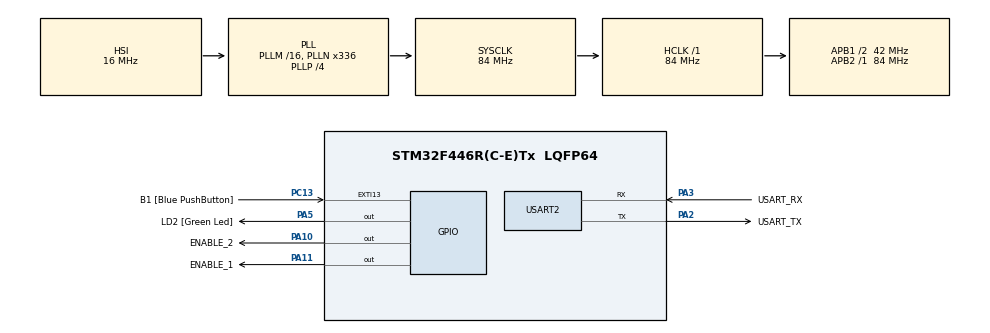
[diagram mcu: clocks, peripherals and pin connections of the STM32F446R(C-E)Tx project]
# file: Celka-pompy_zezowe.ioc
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Mcu.Family=STM32F4
PH0-OSC_IN.Signal=RCC_OSC_IN
VP_SYS_VS_tim6.Mode=TIM6
RCC.CortexFreq_Value=84000000
FREERTOS.BinarySemaphores01=decoder_sem,Dynamic,NULL
NVIC.TIM6_DAC_IRQn=true\:0\:0\:false\:false\:true\:false\:false\:true
PA14.GPIO_Label=TCK
PC13.GPIO_Label=B1 [Blue PushButton]
RCC.SYSCLKSource=RCC_SYSCLKSOURCE_PLLCLK
ProjectManager.StackSize=0x400
RCC.HCLKFreq_Value=84000000
RCC.APB2TimFreq_Value=84000000
RCC.AHBFreq_Value=84000000
PH0-OSC_IN.Mode=HSE-External-Oscillator
FREERTOS.configUSE_PREEMPTION=1
RCC.HSE_VALUE=8000000
PC14-OSC32_IN.Mode=LSE-External-Oscillator
PA14.Mode=Serial_Wire
PA10.GPIO_Label=ENABLE_2
VP_FREERTOS_VS_CMSIS_V1.Mode=CMSIS_V1
RCC.FLatency-AdvancedSettings=FLASH_LATENCY_2
PH1-OSC_OUT.Mode=HSE-External-Oscillator
Mcu.Package=LQFP64
NVIC.TimeBase=TIM6_DAC_IRQn
USART2.VirtualMode=VM_ASYNC
PA2.GPIO_Label=USART_TX
NVIC.TimeBaseIP=TIM6
PA10.Signal=GPIO_Output
RCC.APB1TimFreq_Value=84000000
PA3.Signal=USART2_RX
PB3.GPIO_Label=SWO
PC15-OSC32_OUT.Mode=LSE-External-Oscillator
FREERTOS.Tasks01=defaultTask,0,128,StartDefaultTask,Default,NULL,Dynamic,NULL,NULL;TaskComm,0,256,StartTaskCommunication,As external,NULL,Dynamic,NULL,NULL;task_bilge_pump,0,256,Start_Task_PumpControl,As external,NULL,Dynamic,NULL,NULL
PC13.Signal=GPXTI13
PA11.GPIO_Label=ENABLE_1
RCC.APB1CLKDivider=RCC_HCLK_DIV2
PC14-OSC32_IN.Signal=RCC_OSC32_IN
NVIC.USART2_IRQn=true\:5\:0\:false\:false\:true\:true\:true\:true
PA13.Signal=SYS_JTMS-SWDIO
PA3.Mode=Asynchronous
ProjectManager.TargetToolchain=STM32CubeIDE
RCC.USBFreq_Value=168000000
PC15-OSC32_OUT.Signal=RCC_OSC32_OUT
PA5.Signal=GPIO_Output
board=NUCLEO-F446RE
RCC.VCOOutputFreq_Value=336000000
RCC.APB2Freq_Value=84000000
PH1-OSC_OUT.Signal=RCC_OSC_OUT
PA13.Mode=Serial_Wire
Mcu.Name=STM32F446R(C-E)Tx
PA13.GPIO_Label=TMS
PA2.Signal=USART2_TX
RCC.48MHZClocksFreq_Value=84000000
PB3.Signal=SYS_JTDO-SWO
RCC.SYSCLKFreq_VALUE=84000000
FREERTOS.configUSE_COUNTING_SEMAPHORES=1
PA5.GPIO_Label=LD2 [Green Led]
PC13.GPIO_ModeDefaultEXTI=GPIO_MODE_IT_FALLING
PA11.Signal=GPIO_Output
PA14.Signal=SYS_JTCK-SWCLK
ProjectManager.HeapSize=0x200
RCC.HSI_VALUE=16000000
RCC.PLLP=RCC_PLLP_DIV4
NVIC.PriorityGroup=NVIC_PRIORITYGROUP_4
RCC.PLLN=336
PA2.Mode=Asynchronous
RCC.APB1Freq_Value=42000000
PA3.GPIO_Label=USART_RX

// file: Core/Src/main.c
/* USER CODE BEGIN Header */
/**
  ******************************************************************************
  * @file           : main.c
  * @brief          : Main program body
  ******************************************************************************
  * @attention
  *
  * <h2><center>&copy; Copyright (c) 2021 STMicroelectronics.
  * All rights reserved.</center></h2>
  *
  * This software component is licensed by ST under Ultimate Liberty license
  * SLA0044, the "License"; You may not use this file except in compliance with
  * the License. You may obtain a copy of the License at:
  *                             www.st.com/SLA0044
  *
  ******************************************************************************
  */
/* USER CODE END Header */

#include "main.h"
#include "cmsis_os.h"
#include "usart.h"
#include "gpio.h"

void SystemClock_Config(void);
void MX_FREERTOS_Init(void);

int main(void)
{

  /* MCU Configuration--------------------------------------------------------*/

  /* Reset of all peripherals, Initializes the Flash interface and the Systick. */
  HAL_Init();

  /* Configure the system clock */
  SystemClock_Config();

  /* Initialize all configured peripherals */
  MX_GPIO_Init();
  MX_USART2_UART_Init();

  /* Call init function for freertos objects (in freertos.c) */
  MX_FREERTOS_Init();
  /* Start scheduler */
  osKernelStart();

  /* We should never get here as control is now taken by the scheduler */
  /* Infinite loop */
  while (1)
  {

  }
}

void SystemClock_Config(void)
{
  RCC_OscInitTypeDef RCC_OscInitStruct = {0};
  RCC_ClkInitTypeDef RCC_ClkInitStruct = {0};

  /** Configure the main internal regulator output voltage
  */
  __HAL_RCC_PWR_CLK_ENABLE();
  __HAL_PWR_VOLTAGESCALING_CONFIG(PWR_REGULATOR_VOLTAGE_SCALE3);
  /** Initializes the CPU, AHB and APB busses clocks
  */
  RCC_OscInitStruct.OscillatorType = RCC_OSCILLATORTYPE_HSI;
  RCC_OscInitStruct.HSIState = RCC_HSI_ON;
  RCC_OscInitStruct.HSICalibrationValue = RCC_HSICALIBRATION_DEFAULT;
  RCC_OscInitStruct.PLL.PLLState = RCC_PLL_ON;
  RCC_OscInitStruct.PLL.PLLSource = RCC_PLLSOURCE_HSI;
  RCC_OscInitStruct.PLL.PLLM = 16;
  RCC_OscInitStruct.PLL.PLLN = 336;
  RCC_OscInitStruct.PLL.PLLP = RCC_PLLP_DIV4;
  RCC_OscInitStruct.PLL.PLLQ = 2;
  RCC_OscInitStruct.PLL.PLLR = 2;
  if (HAL_RCC_OscConfig(&RCC_OscInitStruct) != HAL_OK)
  {
    Error_Handler();
  }
  /** Initializes the CPU, AHB and APB busses clocks
  */
  RCC_ClkInitStruct.ClockType = RCC_CLOCKTYPE_HCLK|RCC_CLOCKTYPE_SYSCLK
                              |RCC_CLOCKTYPE_PCLK1|RCC_CLOCKTYPE_PCLK2;
  RCC_ClkInitStruct.SYSCLKSource = RCC_SYSCLKSOURCE_PLLCLK;
  RCC_ClkInitStruct.AHBCLKDivider = RCC_SYSCLK_DIV1;
  RCC_ClkInitStruct.APB1CLKDivider = RCC_HCLK_DIV2;
  RCC_ClkInitStruct.APB2CLKDivider = RCC_HCLK_DIV1;

  if (HAL_RCC_ClockConfig(&RCC_ClkInitStruct, FLASH_LATENCY_2) != HAL_OK)
  {
    Error_Handler();
  }
}

 /**
  * @brief  Period elapsed callback in non blocking mode
  * @note   This function is called  when TIM6 interrupt took place, inside
  * HAL_TIM_IRQHandler(). It makes a direct call to HAL_IncTick() to increment
  * a global variable "uwTick" used as application time base.
  * @param  htim : TIM handle
  * @retval None
  */
void HAL_TIM_PeriodElapsedCallback(TIM_HandleTypeDef *htim)
{
  if (htim->Instance == TIM6) {
    HAL_IncTick();
  }
}

void Error_Handler(void)
{
}

/************************ (C) COPYRIGHT STMicroelectronics *****END OF FILE****/

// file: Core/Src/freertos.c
/* USER CODE BEGIN Header */
/**
  ******************************************************************************
  * File Name          : freertos.c
  * Description        : Code for freertos applications
  ******************************************************************************
  * @attention
  *
  * <h2><center>&copy; Copyright (c) 2021 STMicroelectronics.
  * All rights reserved.</center></h2>
  *
  * This software component is licensed by ST under Ultimate Liberty license
  * SLA0044, the "License"; You may not use this file except in compliance with
  * the License. You may obtain a copy of the License at:
  *                             www.st.com/SLA0044
  *
  ******************************************************************************
  */
/* USER CODE END Header */

#include "FreeRTOS.h"
#include "task.h"
#include "main.h"
#include "cmsis_os.h"

/* USER CODE BEGIN Includes */
#include "taskCommunication.h"
#include "task_bilge_pump.h"
/* USER CODE END Includes */

osThreadId defaultTaskHandle;
osThreadId TaskCommHandle;
osThreadId task_bilge_pumpHandle;
osSemaphoreId decoder_semHandle;

void StartDefaultTask(void const * argument);
extern void StartTaskCommunication(void const * argument);
extern void Start_Task_PumpControl(void const * argument);

void MX_FREERTOS_Init(void); /* (MISRA C 2004 rule 8.1) */

/* GetIdleTaskMemory prototype (linked to static allocation support) */
void vApplicationGetIdleTaskMemory( StaticTask_t **ppxIdleTaskTCBBuffer, StackType_t **ppxIdleTaskStackBuffer, uint32_t *pulIdleTaskStackSize );

/* USER CODE BEGIN GET_IDLE_TASK_MEMORY */
static StaticTask_t xIdleTaskTCBBuffer;
static StackType_t xIdleStack[configMINIMAL_STACK_SIZE];

void vApplicationGetIdleTaskMemory( StaticTask_t **ppxIdleTaskTCBBuffer, StackType_t **ppxIdleTaskStackBuffer, uint32_t *pulIdleTaskStackSize )
{
  *ppxIdleTaskTCBBuffer = &xIdleTaskTCBBuffer;
  *ppxIdleTaskStackBuffer = &xIdleStack[0];
  *pulIdleTaskStackSize = configMINIMAL_STACK_SIZE;
  /* place for user code */
}
/* USER CODE END GET_IDLE_TASK_MEMORY */

void MX_FREERTOS_Init(void) {

  /* Create the semaphores(s) */
  /* definition and creation of decoder_sem */
  osSemaphoreDef(decoder_sem);
  decoder_semHandle = osSemaphoreCreate(osSemaphore(decoder_sem), 1);

  /* Create the thread(s) */
  /* definition and creation of defaultTask */
  osThreadDef(defaultTask, StartDefaultTask, osPriorityNormal, 0, 128);
  defaultTaskHandle = osThreadCreate(osThread(defaultTask), NULL);

  /* definition and creation of TaskComm */
  osThreadDef(TaskComm, StartTaskCommunication, osPriorityNormal, 0, 256);
  TaskCommHandle = osThreadCreate(osThread(TaskComm), NULL);

  /* definition and creation of task_bilge_pump */
  osThreadDef(task_bilge_pump, Start_Task_PumpControl, osPriorityNormal, 0, 256);
  task_bilge_pumpHandle = osThreadCreate(osThread(task_bilge_pump), NULL);

}

void StartDefaultTask(void const * argument)
{
  /* USER CODE BEGIN StartDefaultTask */
  /* Infinite loop */
  for(;;)
  {
    osDelay(100);
  }
  /* USER CODE END StartDefaultTask */
}

/************************ (C) COPYRIGHT STMicroelectronics *****END OF FILE****/
